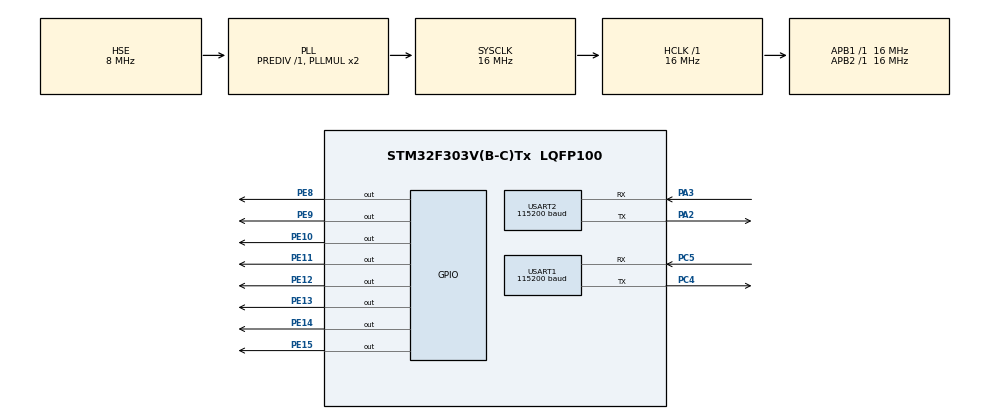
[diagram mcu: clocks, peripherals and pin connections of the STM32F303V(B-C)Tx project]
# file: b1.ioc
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Dma.Request0=USART2_RX
Dma.Request1=USART2_TX
Dma.Request2=USART1_RX
Dma.Request3=USART1_TX
Dma.USART1_RX.2.Direction=DMA_PERIPH_TO_MEMORY
Dma.USART1_RX.2.Instance=DMA1_Channel5
Dma.USART1_RX.2.MemDataAlignment=DMA_MDATAALIGN_BYTE
Dma.USART1_RX.2.MemInc=DMA_MINC_ENABLE
Dma.USART1_RX.2.Mode=DMA_NORMAL
Dma.USART1_RX.2.PeriphDataAlignment=DMA_PDATAALIGN_BYTE
Dma.USART1_RX.2.PeriphInc=DMA_PINC_DISABLE
Dma.USART1_RX.2.Priority=DMA_PRIORITY_LOW
Dma.USART1_TX.3.Direction=DMA_MEMORY_TO_PERIPH
Dma.USART1_TX.3.Instance=DMA1_Channel4
Dma.USART1_TX.3.MemDataAlignment=DMA_MDATAALIGN_BYTE
Dma.USART1_TX.3.MemInc=DMA_MINC_ENABLE
Dma.USART1_TX.3.Mode=DMA_NORMAL
Dma.USART1_TX.3.PeriphDataAlignment=DMA_PDATAALIGN_BYTE
Dma.USART1_TX.3.PeriphInc=DMA_PINC_DISABLE
Dma.USART1_TX.3.Priority=DMA_PRIORITY_LOW
Dma.USART2_RX.0.Direction=DMA_PERIPH_TO_MEMORY
Dma.USART2_RX.0.Instance=DMA1_Channel6
Dma.USART2_RX.0.MemDataAlignment=DMA_MDATAALIGN_BYTE
Dma.USART2_RX.0.MemInc=DMA_MINC_ENABLE
Dma.USART2_RX.0.Mode=DMA_NORMAL
Dma.USART2_RX.0.PeriphDataAlignment=DMA_PDATAALIGN_BYTE
Dma.USART2_RX.0.PeriphInc=DMA_PINC_DISABLE
Dma.USART2_RX.0.Priority=DMA_PRIORITY_LOW
Dma.USART2_TX.1.Direction=DMA_MEMORY_TO_PERIPH
Dma.USART2_TX.1.Instance=DMA1_Channel7
Dma.USART2_TX.1.MemDataAlignment=DMA_MDATAALIGN_BYTE
Dma.USART2_TX.1.MemInc=DMA_MINC_ENABLE
Dma.USART2_TX.1.Mode=DMA_NORMAL
Dma.USART2_TX.1.PeriphDataAlignment=DMA_PDATAALIGN_BYTE
Dma.USART2_TX.1.PeriphInc=DMA_PINC_DISABLE
Dma.USART2_TX.1.Priority=DMA_PRIORITY_LOW
Mcu.Family=STM32F3
Mcu.Name=STM32F303V(B-C)Tx
Mcu.Package=LQFP100
NVIC.DMA1_Channel4_IRQn=true\:0\:0\:false\:false\:true\:false
NVIC.DMA1_Channel5_IRQn=true\:0\:0\:false\:false\:true\:false
NVIC.DMA1_Channel6_IRQn=true\:0\:0\:false\:false\:true\:false
NVIC.DMA1_Channel7_IRQn=true\:0\:0\:false\:false\:true\:false
NVIC.PriorityGroup=NVIC_PRIORITYGROUP_4
NVIC.USART1_IRQn=true\:0\:0\:false\:false\:true\:true
NVIC.USART2_IRQn=true\:0\:0\:false\:false\:true\:true
PA13.Mode=Serial_Wire
PA13.Signal=SYS_JTMS-SWDIO
PA14.Mode=Serial_Wire
PA14.Signal=SYS_JTCK-SWCLK
PA2.Mode=Asynchronous
PA2.Signal=USART2_TX
PA3.Mode=Asynchronous
PA3.Signal=USART2_RX
PC4.Mode=Asynchronous
PC4.Signal=USART1_TX
PC5.Mode=Asynchronous
PC5.Signal=USART1_RX
PE10.Signal=GPIO_Output
PE11.Signal=GPIO_Output
PE12.Signal=GPIO_Output
PE13.Signal=GPIO_Output
PE14.Signal=GPIO_Output
PE15.Signal=GPIO_Output
PE8.Signal=GPIO_Output
PE9.Signal=GPIO_Output
PF0-OSC_IN.Mode=HSE-External-Oscillator
PF0-OSC_IN.Signal=RCC_OSC_IN
PF1-OSC_OUT.Mode=HSE-External-Oscillator
PF1-OSC_OUT.Signal=RCC_OSC_OUT
ProjectManager.HeapSize=0x200
ProjectManager.StackSize=0x400
ProjectManager.TargetToolchain=EWARM
RCC.AHBFreq_Value=16000000
RCC.APB1Freq_Value=16000000
RCC.APB1TimFreq_Value=16000000
RCC.APB2Freq_Value=16000000
RCC.APB2TimFreq_Value=16000000
RCC.CortexFreq_Value=16000000
RCC.HCLKFreq_Value=16000000
RCC.HSE_VALUE=8000000
RCC.HSI_VALUE=8000000
RCC.LSE_VALUE=32768
RCC.PLLSourceVirtual=RCC_PLLSOURCE_HSE
RCC.SYSCLKFreq_VALUE=16000000
RCC.SYSCLKSourceVirtual=RCC_SYSCLKSOURCE_PLLCLK
RCC.USBFreq_Value=16000000
USART1.BaudRate=115200
USART1.Parity=PARITY_EVEN
USART1.VirtualMode-Asynchronous=VM_ASYNC
USART1.WordLength=WORDLENGTH_9B
USART2.BaudRate=115200
USART2.Parity=PARITY_EVEN
USART2.VirtualMode-Asynchronous=VM_ASYNC
USART2.WordLength=WORDLENGTH_9B
board=b1

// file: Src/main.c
/**
  ******************************************************************************
  * @file           : main.c
  * @brief          : Main program body
  ******************************************************************************
  ** This notice applies to any and all portions of this file
  * that are not between comment pairs USER CODE BEGIN and
  * USER CODE END. Other portions of this file, whether
  * inserted by the user or by software development tools
  * are owned by their respective copyright owners.
  *
  * COPYRIGHT(c) 2018 STMicroelectronics
  *
  * Redistribution and use in source and binary forms, with or without modification,
  * are permitted provided that the following conditions are met:
  *   1. Redistributions of source code must retain the above copyright notice,
  *      this list of conditions and the following disclaimer.
  *   2. Redistributions in binary form must reproduce the above copyright notice,
  *      this list of conditions and the following disclaimer in the documentation
  *      and/or other materials provided with the distribution.
  *   3. Neither the name of STMicroelectronics nor the names of its contributors
  *      may be used to endorse or promote products derived from this software
  *      without specific prior written permission.
  *
  * THIS SOFTWARE IS PROVIDED BY THE COPYRIGHT HOLDERS AND CONTRIBUTORS "AS IS"
  * AND ANY EXPRESS OR IMPLIED WARRANTIES, INCLUDING, BUT NOT LIMITED TO, THE
  * IMPLIED WARRANTIES OF MERCHANTABILITY AND FITNESS FOR A PARTICULAR PURPOSE ARE
  * DISCLAIMED. IN NO EVENT SHALL THE COPYRIGHT HOLDER OR CONTRIBUTORS BE LIABLE
  * FOR ANY DIRECT, INDIRECT, INCIDENTAL, SPECIAL, EXEMPLARY, OR CONSEQUENTIAL
  * DAMAGES (INCLUDING, BUT NOT LIMITED TO, PROCUREMENT OF SUBSTITUTE GOODS OR
  * SERVICES; LOSS OF USE, DATA, OR PROFITS; OR BUSINESS INTERRUPTION) HOWEVER
  * CAUSED AND ON ANY THEORY OF LIABILITY, WHETHER IN CONTRACT, STRICT LIABILITY,
  * OR TORT (INCLUDING NEGLIGENCE OR OTHERWISE) ARISING IN ANY WAY OUT OF THE USE
  * OF THIS SOFTWARE, EVEN IF ADVISED OF THE POSSIBILITY OF SUCH DAMAGE.
  *
  ******************************************************************************
  */
#include "main.h"
#include "stm32f3xx_hal.h"

/* USER CODE BEGIN Includes */
#include "app.h"
/* USER CODE END Includes */

UART_HandleTypeDef huart1;
UART_HandleTypeDef huart2;
DMA_HandleTypeDef hdma_usart1_rx;
DMA_HandleTypeDef hdma_usart1_tx;
DMA_HandleTypeDef hdma_usart2_rx;
DMA_HandleTypeDef hdma_usart2_tx;

/* USER CODE BEGIN PV */
/* Private variables ---------------------------------------------------------*/

/* USER CODE END PV */

void SystemClock_Config(void);
static void MX_GPIO_Init(void);
static void MX_DMA_Init(void);
static void MX_USART1_UART_Init(void);
static void MX_USART2_UART_Init(void);

/* USER CODE BEGIN PFP */
/* Private function prototypes -----------------------------------------------*/

/* USER CODE END PFP */

int main(void)
{

  /* MCU Configuration----------------------------------------------------------*/

  /* Reset of all peripherals, Initializes the Flash interface and the Systick. */
  HAL_Init();

  /* Configure the system clock */
  SystemClock_Config();

  /* Initialize all configured peripherals */
  MX_GPIO_Init();
  MX_DMA_Init();
  MX_USART1_UART_Init();
  MX_USART2_UART_Init();
  /* USER CODE BEGIN 2 */
  AppInit();
  /* USER CODE END 2 */

  /* Infinite loop */
  /* USER CODE BEGIN WHILE */
  while (1)
  {
    AppWork();
  /* USER CODE END WHILE */

  }

}

void SystemClock_Config(void)
{

  RCC_OscInitTypeDef RCC_OscInitStruct;
  RCC_ClkInitTypeDef RCC_ClkInitStruct;
  RCC_PeriphCLKInitTypeDef PeriphClkInit;

    /**Initializes the CPU, AHB and APB busses clocks
    */
  RCC_OscInitStruct.OscillatorType = RCC_OSCILLATORTYPE_HSE;
  RCC_OscInitStruct.HSEState = RCC_HSE_ON;
  RCC_OscInitStruct.HSEPredivValue = RCC_HSE_PREDIV_DIV1;
  RCC_OscInitStruct.HSIState = RCC_HSI_ON;
  RCC_OscInitStruct.PLL.PLLState = RCC_PLL_ON;
  RCC_OscInitStruct.PLL.PLLSource = RCC_PLLSOURCE_HSE;
  RCC_OscInitStruct.PLL.PLLMUL = RCC_PLL_MUL2;
  if (HAL_RCC_OscConfig(&RCC_OscInitStruct) != HAL_OK)
  {
    _Error_Handler(__FILE__, __LINE__);
  }

    /**Initializes the CPU, AHB and APB busses clocks
    */
  RCC_ClkInitStruct.ClockType = RCC_CLOCKTYPE_HCLK|RCC_CLOCKTYPE_SYSCLK
                              |RCC_CLOCKTYPE_PCLK1|RCC_CLOCKTYPE_PCLK2;
  RCC_ClkInitStruct.SYSCLKSource = RCC_SYSCLKSOURCE_PLLCLK;
  RCC_ClkInitStruct.AHBCLKDivider = RCC_SYSCLK_DIV1;
  RCC_ClkInitStruct.APB1CLKDivider = RCC_HCLK_DIV1;
  RCC_ClkInitStruct.APB2CLKDivider = RCC_HCLK_DIV1;

  if (HAL_RCC_ClockConfig(&RCC_ClkInitStruct, FLASH_LATENCY_0) != HAL_OK)
  {
    _Error_Handler(__FILE__, __LINE__);
  }

  PeriphClkInit.PeriphClockSelection = RCC_PERIPHCLK_USART1|RCC_PERIPHCLK_USART2;
  PeriphClkInit.Usart1ClockSelection = RCC_USART1CLKSOURCE_PCLK2;
  PeriphClkInit.Usart2ClockSelection = RCC_USART2CLKSOURCE_PCLK1;
  if (HAL_RCCEx_PeriphCLKConfig(&PeriphClkInit) != HAL_OK)
  {
    _Error_Handler(__FILE__, __LINE__);
  }

    /**Configure the Systick interrupt time
    */
  HAL_SYSTICK_Config(HAL_RCC_GetHCLKFreq()/1000);

    /**Configure the Systick
    */
  HAL_SYSTICK_CLKSourceConfig(SYSTICK_CLKSOURCE_HCLK);

  /* SysTick_IRQn interrupt configuration */
  HAL_NVIC_SetPriority(SysTick_IRQn, 0, 0);
}

/* USART1 init function */
static void MX_USART1_UART_Init(void)
{

  huart1.Instance = USART1;
  huart1.Init.BaudRate = 115200;
  huart1.Init.WordLength = UART_WORDLENGTH_9B;
  huart1.Init.StopBits = UART_STOPBITS_1;
  huart1.Init.Parity = UART_PARITY_EVEN;
  huart1.Init.Mode = UART_MODE_TX_RX;
  huart1.Init.HwFlowCtl = UART_HWCONTROL_NONE;
  huart1.Init.OverSampling = UART_OVERSAMPLING_16;
  huart1.Init.OneBitSampling = UART_ONE_BIT_SAMPLE_DISABLE;
  huart1.AdvancedInit.AdvFeatureInit = UART_ADVFEATURE_NO_INIT;
  if (HAL_UART_Init(&huart1) != HAL_OK)
  {
    _Error_Handler(__FILE__, __LINE__);
  }

}

/* USART2 init function */
static void MX_USART2_UART_Init(void)
{

  huart2.Instance = USART2;
  huart2.Init.BaudRate = 115200;
  huart2.Init.WordLength = UART_WORDLENGTH_9B;
  huart2.Init.StopBits = UART_STOPBITS_1;
  huart2.Init.Parity = UART_PARITY_EVEN;
  huart2.Init.Mode = UART_MODE_TX_RX;
  huart2.Init.HwFlowCtl = UART_HWCONTROL_NONE;
  huart2.Init.OverSampling = UART_OVERSAMPLING_16;
  huart2.Init.OneBitSampling = UART_ONE_BIT_SAMPLE_DISABLE;
  huart2.AdvancedInit.AdvFeatureInit = UART_ADVFEATURE_NO_INIT;
  if (HAL_UART_Init(&huart2) != HAL_OK)
  {
    _Error_Handler(__FILE__, __LINE__);
  }

}

static void MX_DMA_Init(void)
{
  /* DMA controller clock enable */
  __HAL_RCC_DMA1_CLK_ENABLE();

  /* DMA interrupt init */
  /* DMA1_Channel4_IRQn interrupt configuration */
  HAL_NVIC_SetPriority(DMA1_Channel4_IRQn, 0, 0);
  HAL_NVIC_EnableIRQ(DMA1_Channel4_IRQn);
  /* DMA1_Channel5_IRQn interrupt configuration */
  HAL_NVIC_SetPriority(DMA1_Channel5_IRQn, 0, 0);
  HAL_NVIC_EnableIRQ(DMA1_Channel5_IRQn);
  /* DMA1_Channel6_IRQn interrupt configuration */
  HAL_NVIC_SetPriority(DMA1_Channel6_IRQn, 0, 0);
  HAL_NVIC_EnableIRQ(DMA1_Channel6_IRQn);
  /* DMA1_Channel7_IRQn interrupt configuration */
  HAL_NVIC_SetPriority(DMA1_Channel7_IRQn, 0, 0);
  HAL_NVIC_EnableIRQ(DMA1_Channel7_IRQn);

}

/** Configure pins as
        * Analog
        * Input
        * Output
        * EVENT_OUT
        * EXTI
*/
static void MX_GPIO_Init(void)
{

  GPIO_InitTypeDef GPIO_InitStruct;

  /* GPIO Ports Clock Enable */
  __HAL_RCC_GPIOF_CLK_ENABLE();
  __HAL_RCC_GPIOA_CLK_ENABLE();
  __HAL_RCC_GPIOC_CLK_ENABLE();
  __HAL_RCC_GPIOE_CLK_ENABLE();

  /*Configure GPIO pin Output Level */
  HAL_GPIO_WritePin(GPIOE, GPIO_PIN_8|GPIO_PIN_9|GPIO_PIN_10|GPIO_PIN_11
                          |GPIO_PIN_12|GPIO_PIN_13|GPIO_PIN_14|GPIO_PIN_15, GPIO_PIN_RESET);

  /*Configure GPIO pins : PE8 PE9 PE10 PE11
                           PE12 PE13 PE14 PE15 */
  GPIO_InitStruct.Pin = GPIO_PIN_8|GPIO_PIN_9|GPIO_PIN_10|GPIO_PIN_11
                          |GPIO_PIN_12|GPIO_PIN_13|GPIO_PIN_14|GPIO_PIN_15;
  GPIO_InitStruct.Mode = GPIO_MODE_OUTPUT_PP;
  GPIO_InitStruct.Pull = GPIO_NOPULL;
  GPIO_InitStruct.Speed = GPIO_SPEED_FREQ_LOW;
  HAL_GPIO_Init(GPIOE, &GPIO_InitStruct);

}

void _Error_Handler(char *file, int line)
{
  while(1)
  {
  }
}

/************************ (C) COPYRIGHT STMicroelectronics *****END OF FILE****/
